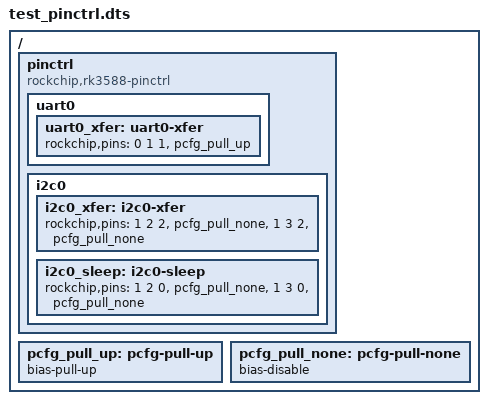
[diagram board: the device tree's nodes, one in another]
/dts-v1/;

/ {
    pinctrl: pinctrl {
        compatible = "rockchip,rk3588-pinctrl";
        
        uart0 {
            uart0_xfer: uart0-xfer {
                rockchip,pins = <0 1 1 &pcfg_pull_up>;
            };
        };
        
        i2c0 {
            i2c0_xfer: i2c0-xfer {
                rockchip,pins = <1 2 2 &pcfg_pull_none>, <1 3 2 &pcfg_pull_none>;
            };
            i2c0_sleep: i2c0-sleep {
                rockchip,pins = <1 2 0 &pcfg_pull_none>, <1 3 0 &pcfg_pull_none>;
            };
        };
    };
    
    pcfg_pull_up: pcfg-pull-up {
        bias-pull-up;
    };
    pcfg_pull_none: pcfg-pull-none {
        bias-disable;
    };
};
